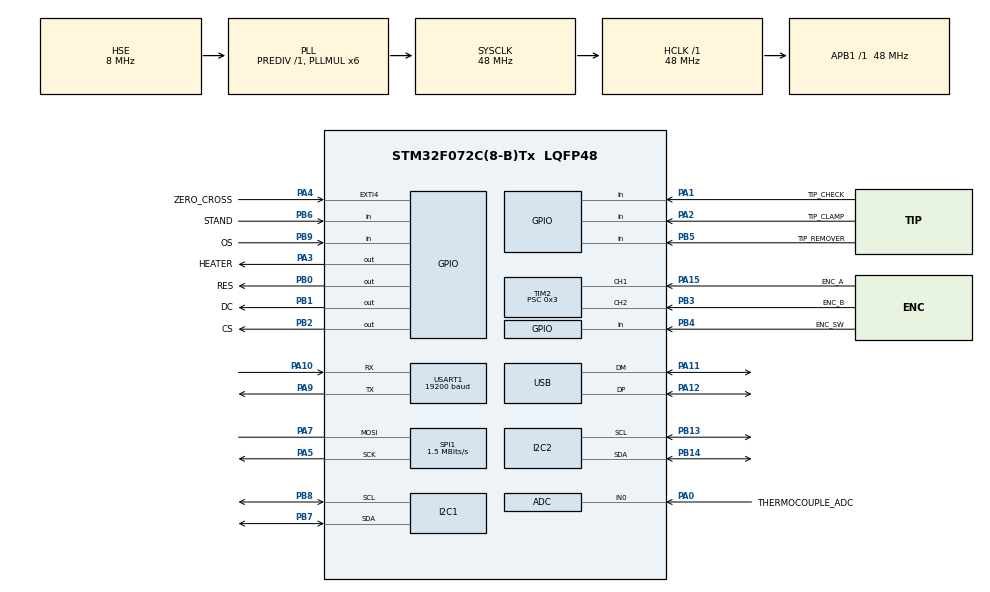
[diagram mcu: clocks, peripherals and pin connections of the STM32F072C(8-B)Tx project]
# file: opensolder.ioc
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ADC.ContinuousConvMode=ENABLE
ADC.SamplingTime=ADC_SAMPLETIME_239CYCLES_5
Dma.ADC.0.Direction=DMA_PERIPH_TO_MEMORY
Dma.ADC.0.Instance=DMA1_Channel1
Dma.ADC.0.MemDataAlignment=DMA_MDATAALIGN_HALFWORD
Dma.ADC.0.MemInc=DMA_MINC_ENABLE
Dma.ADC.0.Mode=DMA_NORMAL
Dma.ADC.0.PeriphDataAlignment=DMA_PDATAALIGN_HALFWORD
Dma.ADC.0.PeriphInc=DMA_PINC_DISABLE
Dma.ADC.0.Priority=DMA_PRIORITY_LOW
Dma.Request0=ADC
I2C2.Timing=0x20303E5D
Mcu.Family=STM32F0
Mcu.Name=STM32F072C(8-B)Tx
Mcu.Package=LQFP48
NVIC.DMA1_Channel1_IRQn=true\:0\:0\:false\:false\:true\:false\:true\:true
NVIC.EXTI4_15_IRQn=true\:0\:0\:false\:false\:true\:true\:true\:true
NVIC.TIM14_IRQn=true\:0\:0\:false\:false\:true\:true\:true\:true
NVIC.TIM6_DAC_IRQn=true\:0\:0\:false\:false\:true\:true\:true\:true
NVIC.TIM7_IRQn=true\:0\:0\:false\:false\:true\:true\:true\:true
NVIC.USB_IRQn=true\:0\:0\:false\:false\:true\:false\:true\:true
PA0.GPIO_Label=THERMOCOUPLE_ADC
PA0.Mode=IN0
PA0.Signal=ADC_IN0
PA1.GPIO_Label=TIP_CHECK
PA1.Signal=GPIO_Input
PA10.Mode=Asynchronous
PA10.Signal=USART1_RX
PA11.Mode=Device
PA11.Signal=USB_DM
PA12.Mode=Device
PA12.Signal=USB_DP
PA13.Mode=Serial_Wire
PA13.Signal=SYS_SWDIO
PA14.Mode=Serial_Wire
PA14.Signal=SYS_SWCLK
PA15.GPIO_Label=ENC_A
PA15.Signal=S_TIM2_CH1_ETR
PA2.GPIO_Label=TIP_CLAMP
PA2.Signal=GPIO_Input
PA3.GPIO_Label=HEATER
PA3.Signal=GPIO_Output
PA4.GPIO_Label=ZERO_CROSS
PA4.GPIO_PuPd=GPIO_PULLUP
PA4.Signal=GPXTI4
PA5.Mode=Simplex_Bidirectional_Master
PA5.Signal=SPI1_SCK
PA7.Mode=Simplex_Bidirectional_Master
PA7.Signal=SPI1_MOSI
PA9.Mode=Asynchronous
PA9.Signal=USART1_TX
PB0.GPIO_Label=RES
PB0.Signal=GPIO_Output
PB1.GPIO_Label=DC
PB1.Signal=GPIO_Output
PB13.Mode=I2C
PB13.Signal=I2C2_SCL
PB14.Mode=I2C
PB14.Signal=I2C2_SDA
PB2.GPIO_Label=CS
PB2.Signal=GPIO_Output
PB3.GPIO_Label=ENC_B
PB3.Signal=S_TIM2_CH2
PB4.GPIO_Label=ENC_SW
PB4.Signal=GPIO_Input
PB5.GPIO_Label=TIP_REMOVER
PB5.GPIO_PuPd=GPIO_NOPULL
PB5.Signal=GPIO_Input
PB6.GPIO_Label=STAND
PB6.GPIO_PuPd=GPIO_NOPULL
PB6.Signal=GPIO_Input
PB7.Mode=I2C
PB7.Signal=I2C1_SDA
PB8.Mode=I2C
PB8.Signal=I2C1_SCL
PB9.GPIO_Label=OS
PB9.GPIO_PuPd=GPIO_PULLUP
PB9.Signal=GPIO_Input
PF0-OSC_IN.Mode=HSE-External-Oscillator
PF0-OSC_IN.Signal=RCC_OSC_IN
PF1-OSC_OUT.Mode=HSE-External-Oscillator
PF1-OSC_OUT.Signal=RCC_OSC_OUT
ProjectManager.HeapSize=0x200
ProjectManager.StackSize=0x400
ProjectManager.TargetToolchain=STM32CubeIDE
RCC.AHBFreq_Value=48000000
RCC.APB1Freq_Value=48000000
RCC.APB1TimFreq_Value=48000000
RCC.HCLKFreq_Value=48000000
RCC.PLLMUL=RCC_PLL_MUL6
RCC.PLLSourceVirtual=RCC_PLLSOURCE_HSE
RCC.SYSCLKFreq_VALUE=48000000
RCC.SYSCLKSource=RCC_SYSCLKSOURCE_PLLCLK
SH.S_TIM2_CH1_ETR.0=TIM2_CH1,Encoder_Interface
SH.S_TIM2_CH2.0=TIM2_CH2,Encoder_Interface
SPI1.BaudRatePrescaler=SPI_BAUDRATEPRESCALER_32
SPI1.CLKPolarity=SPI_POLARITY_HIGH
SPI1.CalculateBaudRate=1.5 MBits/s
SPI1.DataSize=SPI_DATASIZE_8BIT
SPI1.Direction=SPI_DIRECTION_1LINE
SPI1.Mode=SPI_MODE_MASTER
SPI1.VirtualType=VM_MASTER
TIM14.AutoReloadPreload=TIM_AUTORELOAD_PRELOAD_ENABLE
TIM14.Period=1999
TIM14.Prescaler=47
TIM2.EncoderMode=TIM_ENCODERMODE_TI12
TIM2.IC1Filter=5
TIM2.IC1Polarity=TIM_ICPOLARITY_FALLING
TIM2.IC2Filter=5
TIM2.IC2Polarity=TIM_ICPOLARITY_FALLING
TIM2.Period=0xffffffff
TIM2.Prescaler=0x3
TIM6.Period=90
TIM6.Prescaler=47
TIM7.Period=1999
TIM7.Prescaler=47
USART1.BaudRate=19200
USART1.VirtualMode-Asynchronous=VM_ASYNC
USB_DEVICE.CLASS_NAME_FS=CDC
USB_DEVICE.VirtualMode=Cdc
USB_DEVICE.VirtualModeFS=Cdc_FS
VP_TIM14_VS_ClockSourceINT.Mode=Enable_Timer
VP_TIM6_VS_ClockSourceINT.Mode=Enable_Timer
VP_TIM7_VS_ClockSourceINT.Mode=Enable_Timer
VP_USB_DEVICE_VS_USB_DEVICE_CDC_FS.Mode=CDC_FS
board=custom

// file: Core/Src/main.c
/* USER CODE BEGIN Header */
/**
  ******************************************************************************
  * @file           : main.c
  * @brief          : Main program body
  ******************************************************************************
  * @attention
  *
  * <h2><center>&copy; Copyright (c) 2021 STMicroelectronics.
  * All rights reserved.</center></h2>
  *
  * This software component is licensed by ST under BSD 3-Clause license,
  * the "License"; You may not use this file except in compliance with the
  * License. You may obtain a copy of the License at:
  *                        opensource.org/licenses/BSD-3-Clause
  *
  ******************************************************************************
  */
/* USER CODE END Header */
#include "main.h"
#include "usb_device.h"

/* USER CODE BEGIN Includes */
#include "opensolder.h"

/* USER CODE END Includes */

ADC_HandleTypeDef hadc;
DMA_HandleTypeDef hdma_adc;

I2C_HandleTypeDef hi2c1;
I2C_HandleTypeDef hi2c2;

SPI_HandleTypeDef hspi1;

TIM_HandleTypeDef htim2;
TIM_HandleTypeDef htim6;
TIM_HandleTypeDef htim7;
TIM_HandleTypeDef htim14;

UART_HandleTypeDef huart1;

void SystemClock_Config(void);
static void MX_GPIO_Init(void);
static void MX_DMA_Init(void);
static void MX_ADC_Init(void);
static void MX_SPI1_Init(void);
static void MX_TIM2_Init(void);
static void MX_TIM6_Init(void);
static void MX_TIM7_Init(void);
static void MX_I2C1_Init(void);
static void MX_I2C2_Init(void);
static void MX_USART1_UART_Init(void);
static void MX_TIM14_Init(void);

int main(void)
{

  /* MCU Configuration--------------------------------------------------------*/

  /* Reset of all peripherals, Initializes the Flash interface and the Systick. */
  HAL_Init();

  /* Configure the system clock */
  SystemClock_Config();

  /* Initialize all configured peripherals */
  MX_GPIO_Init();
  MX_DMA_Init();
  MX_ADC_Init();
  MX_SPI1_Init();
  MX_TIM2_Init();
  MX_TIM6_Init();
  MX_TIM7_Init();
  MX_I2C1_Init();
  MX_I2C2_Init();
  MX_USART1_UART_Init();
  MX_USB_DEVICE_Init();
  MX_TIM14_Init();
  /* USER CODE BEGIN 2 */

  opensolder_init();

  /* USER CODE END 2 */

  /* Infinite loop */
  /* USER CODE BEGIN WHILE */
  while (1)
  {

	opensolder_main();

    /* USER CODE END WHILE */

  }
}

void SystemClock_Config(void)
{
  RCC_OscInitTypeDef RCC_OscInitStruct = {0};
  RCC_ClkInitTypeDef RCC_ClkInitStruct = {0};
  RCC_PeriphCLKInitTypeDef PeriphClkInit = {0};

  /** Initializes the RCC Oscillators according to the specified parameters
  * in the RCC_OscInitTypeDef structure.
  */
  RCC_OscInitStruct.OscillatorType = RCC_OSCILLATORTYPE_HSI|RCC_OSCILLATORTYPE_HSI14
                              |RCC_OSCILLATORTYPE_HSI48|RCC_OSCILLATORTYPE_HSE;
  RCC_OscInitStruct.HSEState = RCC_HSE_ON;
  RCC_OscInitStruct.HSIState = RCC_HSI_ON;
  RCC_OscInitStruct.HSI48State = RCC_HSI48_ON;
  RCC_OscInitStruct.HSI14State = RCC_HSI14_ON;
  RCC_OscInitStruct.HSICalibrationValue = RCC_HSICALIBRATION_DEFAULT;
  RCC_OscInitStruct.HSI14CalibrationValue = 16;
  RCC_OscInitStruct.PLL.PLLState = RCC_PLL_ON;
  RCC_OscInitStruct.PLL.PLLSource = RCC_PLLSOURCE_HSE;
  RCC_OscInitStruct.PLL.PLLMUL = RCC_PLL_MUL6;
  RCC_OscInitStruct.PLL.PREDIV = RCC_PREDIV_DIV1;
  if (HAL_RCC_OscConfig(&RCC_OscInitStruct) != HAL_OK)
  {
    Error_Handler();
  }

  /** Initializes the CPU, AHB and APB buses clocks
  */
  RCC_ClkInitStruct.ClockType = RCC_CLOCKTYPE_HCLK|RCC_CLOCKTYPE_SYSCLK
                              |RCC_CLOCKTYPE_PCLK1;
  RCC_ClkInitStruct.SYSCLKSource = RCC_SYSCLKSOURCE_PLLCLK;
  RCC_ClkInitStruct.AHBCLKDivider = RCC_SYSCLK_DIV1;
  RCC_ClkInitStruct.APB1CLKDivider = RCC_HCLK_DIV1;

  if (HAL_RCC_ClockConfig(&RCC_ClkInitStruct, FLASH_LATENCY_1) != HAL_OK)
  {
    Error_Handler();
  }
  PeriphClkInit.PeriphClockSelection = RCC_PERIPHCLK_USB|RCC_PERIPHCLK_USART1
                              |RCC_PERIPHCLK_I2C1;
  PeriphClkInit.Usart1ClockSelection = RCC_USART1CLKSOURCE_PCLK1;
  PeriphClkInit.I2c1ClockSelection = RCC_I2C1CLKSOURCE_HSI;
  PeriphClkInit.UsbClockSelection = RCC_USBCLKSOURCE_HSI48;

  if (HAL_RCCEx_PeriphCLKConfig(&PeriphClkInit) != HAL_OK)
  {
    Error_Handler();
  }
}

static void MX_ADC_Init(void)
{

  ADC_ChannelConfTypeDef sConfig = {0};

  /** Configure the global features of the ADC (Clock, Resolution, Data Alignment and number of conversion)
  */
  hadc.Instance = ADC1;
  hadc.Init.ClockPrescaler = ADC_CLOCK_ASYNC_DIV1;
  hadc.Init.Resolution = ADC_RESOLUTION_12B;
  hadc.Init.DataAlign = ADC_DATAALIGN_RIGHT;
  hadc.Init.ScanConvMode = ADC_SCAN_DIRECTION_FORWARD;
  hadc.Init.EOCSelection = ADC_EOC_SINGLE_CONV;
  hadc.Init.LowPowerAutoWait = DISABLE;
  hadc.Init.LowPowerAutoPowerOff = DISABLE;
  hadc.Init.ContinuousConvMode = ENABLE;
  hadc.Init.DiscontinuousConvMode = DISABLE;
  hadc.Init.ExternalTrigConv = ADC_SOFTWARE_START;
  hadc.Init.ExternalTrigConvEdge = ADC_EXTERNALTRIGCONVEDGE_NONE;
  hadc.Init.DMAContinuousRequests = DISABLE;
  hadc.Init.Overrun = ADC_OVR_DATA_PRESERVED;
  if (HAL_ADC_Init(&hadc) != HAL_OK)
  {
    Error_Handler();
  }

  /** Configure for the selected ADC regular channel to be converted.
  */
  sConfig.Channel = ADC_CHANNEL_0;
  sConfig.Rank = ADC_RANK_CHANNEL_NUMBER;
  sConfig.SamplingTime = ADC_SAMPLETIME_239CYCLES_5;
  if (HAL_ADC_ConfigChannel(&hadc, &sConfig) != HAL_OK)
  {
    Error_Handler();
  }

}

static void MX_I2C1_Init(void)
{

  hi2c1.Instance = I2C1;
  hi2c1.Init.Timing = 0x2000090E;
  hi2c1.Init.OwnAddress1 = 0;
  hi2c1.Init.AddressingMode = I2C_ADDRESSINGMODE_7BIT;
  hi2c1.Init.DualAddressMode = I2C_DUALADDRESS_DISABLE;
  hi2c1.Init.OwnAddress2 = 0;
  hi2c1.Init.OwnAddress2Masks = I2C_OA2_NOMASK;
  hi2c1.Init.GeneralCallMode = I2C_GENERALCALL_DISABLE;
  hi2c1.Init.NoStretchMode = I2C_NOSTRETCH_DISABLE;
  if (HAL_I2C_Init(&hi2c1) != HAL_OK)
  {
    Error_Handler();
  }

  /** Configure Analogue filter
  */
  if (HAL_I2CEx_ConfigAnalogFilter(&hi2c1, I2C_ANALOGFILTER_ENABLE) != HAL_OK)
  {
    Error_Handler();
  }

  /** Configure Digital filter
  */
  if (HAL_I2CEx_ConfigDigitalFilter(&hi2c1, 0) != HAL_OK)
  {
    Error_Handler();
  }

}

static void MX_I2C2_Init(void)
{

  hi2c2.Instance = I2C2;
  hi2c2.Init.Timing = 0x20303E5D;
  hi2c2.Init.OwnAddress1 = 0;
  hi2c2.Init.AddressingMode = I2C_ADDRESSINGMODE_7BIT;
  hi2c2.Init.DualAddressMode = I2C_DUALADDRESS_DISABLE;
  hi2c2.Init.OwnAddress2 = 0;
  hi2c2.Init.OwnAddress2Masks = I2C_OA2_NOMASK;
  hi2c2.Init.GeneralCallMode = I2C_GENERALCALL_DISABLE;
  hi2c2.Init.NoStretchMode = I2C_NOSTRETCH_DISABLE;
  if (HAL_I2C_Init(&hi2c2) != HAL_OK)
  {
    Error_Handler();
  }

  /** Configure Analogue filter
  */
  if (HAL_I2CEx_ConfigAnalogFilter(&hi2c2, I2C_ANALOGFILTER_ENABLE) != HAL_OK)
  {
    Error_Handler();
  }

  /** Configure Digital filter
  */
  if (HAL_I2CEx_ConfigDigitalFilter(&hi2c2, 0) != HAL_OK)
  {
    Error_Handler();
  }

}

static void MX_SPI1_Init(void)
{

  /* SPI1 parameter configuration*/
  hspi1.Instance = SPI1;
  hspi1.Init.Mode = SPI_MODE_MASTER;
  hspi1.Init.Direction = SPI_DIRECTION_1LINE;
  hspi1.Init.DataSize = SPI_DATASIZE_8BIT;
  hspi1.Init.CLKPolarity = SPI_POLARITY_HIGH;
  hspi1.Init.CLKPhase = SPI_PHASE_1EDGE;
  hspi1.Init.NSS = SPI_NSS_SOFT;
  hspi1.Init.BaudRatePrescaler = SPI_BAUDRATEPRESCALER_32;
  hspi1.Init.FirstBit = SPI_FIRSTBIT_MSB;
  hspi1.Init.TIMode = SPI_TIMODE_DISABLE;
  hspi1.Init.CRCCalculation = SPI_CRCCALCULATION_DISABLE;
  hspi1.Init.CRCPolynomial = 7;
  hspi1.Init.CRCLength = SPI_CRC_LENGTH_DATASIZE;
  hspi1.Init.NSSPMode = SPI_NSS_PULSE_ENABLE;
  if (HAL_SPI_Init(&hspi1) != HAL_OK)
  {
    Error_Handler();
  }

}

static void MX_TIM2_Init(void)
{

  TIM_Encoder_InitTypeDef sConfig = {0};
  TIM_MasterConfigTypeDef sMasterConfig = {0};

  htim2.Instance = TIM2;
  htim2.Init.Prescaler = 0x3;
  htim2.Init.CounterMode = TIM_COUNTERMODE_UP;
  htim2.Init.Period = 0xffffffff;
  htim2.Init.ClockDivision = TIM_CLOCKDIVISION_DIV1;
  htim2.Init.AutoReloadPreload = TIM_AUTORELOAD_PRELOAD_DISABLE;
  sConfig.EncoderMode = TIM_ENCODERMODE_TI12;
  sConfig.IC1Polarity = TIM_ICPOLARITY_FALLING;
  sConfig.IC1Selection = TIM_ICSELECTION_DIRECTTI;
  sConfig.IC1Prescaler = TIM_ICPSC_DIV1;
  sConfig.IC1Filter = 5;
  sConfig.IC2Polarity = TIM_ICPOLARITY_FALLING;
  sConfig.IC2Selection = TIM_ICSELECTION_DIRECTTI;
  sConfig.IC2Prescaler = TIM_ICPSC_DIV1;
  sConfig.IC2Filter = 5;
  if (HAL_TIM_Encoder_Init(&htim2, &sConfig) != HAL_OK)
  {
    Error_Handler();
  }
  sMasterConfig.MasterOutputTrigger = TIM_TRGO_RESET;
  sMasterConfig.MasterSlaveMode = TIM_MASTERSLAVEMODE_DISABLE;
  if (HAL_TIMEx_MasterConfigSynchronization(&htim2, &sMasterConfig) != HAL_OK)
  {
    Error_Handler();
  }

}

static void MX_TIM6_Init(void)
{

  TIM_MasterConfigTypeDef sMasterConfig = {0};

  htim6.Instance = TIM6;
  htim6.Init.Prescaler = 47;
  htim6.Init.CounterMode = TIM_COUNTERMODE_UP;
  htim6.Init.Period = 90;
  htim6.Init.AutoReloadPreload = TIM_AUTORELOAD_PRELOAD_DISABLE;
  if (HAL_TIM_Base_Init(&htim6) != HAL_OK)
  {
    Error_Handler();
  }
  sMasterConfig.MasterOutputTrigger = TIM_TRGO_RESET;
  sMasterConfig.MasterSlaveMode = TIM_MASTERSLAVEMODE_DISABLE;
  if (HAL_TIMEx_MasterConfigSynchronization(&htim6, &sMasterConfig) != HAL_OK)
  {
    Error_Handler();
  }

}

static void MX_TIM7_Init(void)
{

  TIM_MasterConfigTypeDef sMasterConfig = {0};

  htim7.Instance = TIM7;
  htim7.Init.Prescaler = 47;
  htim7.Init.CounterMode = TIM_COUNTERMODE_UP;
  htim7.Init.Period = 1999;
  htim7.Init.AutoReloadPreload = TIM_AUTORELOAD_PRELOAD_DISABLE;
  if (HAL_TIM_Base_Init(&htim7) != HAL_OK)
  {
    Error_Handler();
  }
  sMasterConfig.MasterOutputTrigger = TIM_TRGO_RESET;
  sMasterConfig.MasterSlaveMode = TIM_MASTERSLAVEMODE_DISABLE;
  if (HAL_TIMEx_MasterConfigSynchronization(&htim7, &sMasterConfig) != HAL_OK)
  {
    Error_Handler();
  }

}

static void MX_TIM14_Init(void)
{

  htim14.Instance = TIM14;
  htim14.Init.Prescaler = 47;
  htim14.Init.CounterMode = TIM_COUNTERMODE_UP;
  htim14.Init.Period = 1999;
  htim14.Init.ClockDivision = TIM_CLOCKDIVISION_DIV1;
  htim14.Init.AutoReloadPreload = TIM_AUTORELOAD_PRELOAD_ENABLE;
  if (HAL_TIM_Base_Init(&htim14) != HAL_OK)
  {
    Error_Handler();
  }

}

static void MX_USART1_UART_Init(void)
{

  huart1.Instance = USART1;
  huart1.Init.BaudRate = 19200;
  huart1.Init.WordLength = UART_WORDLENGTH_8B;
  huart1.Init.StopBits = UART_STOPBITS_1;
  huart1.Init.Parity = UART_PARITY_NONE;
  huart1.Init.Mode = UART_MODE_TX_RX;
  huart1.Init.HwFlowCtl = UART_HWCONTROL_NONE;
  huart1.Init.OverSampling = UART_OVERSAMPLING_16;
  huart1.Init.OneBitSampling = UART_ONE_BIT_SAMPLE_DISABLE;
  huart1.AdvancedInit.AdvFeatureInit = UART_ADVFEATURE_NO_INIT;
  if (HAL_UART_Init(&huart1) != HAL_OK)
  {
    Error_Handler();
  }

}

static void MX_DMA_Init(void)
{

  /* DMA controller clock enable */
  __HAL_RCC_DMA1_CLK_ENABLE();

  /* DMA interrupt init */
  /* DMA1_Channel1_IRQn interrupt configuration */
  HAL_NVIC_SetPriority(DMA1_Channel1_IRQn, 0, 0);
  HAL_NVIC_EnableIRQ(DMA1_Channel1_IRQn);

}

static void MX_GPIO_Init(void)
{
  GPIO_InitTypeDef GPIO_InitStruct = {0};

  /* GPIO Ports Clock Enable */
  __HAL_RCC_GPIOF_CLK_ENABLE();
  __HAL_RCC_GPIOA_CLK_ENABLE();
  __HAL_RCC_GPIOB_CLK_ENABLE();

  /*Configure GPIO pin Output Level */
  HAL_GPIO_WritePin(HEATER_GPIO_Port, HEATER_Pin, GPIO_PIN_RESET);

  /*Configure GPIO pin Output Level */
  HAL_GPIO_WritePin(GPIOB, RES_Pin|DC_Pin|CS_Pin, GPIO_PIN_RESET);

  /*Configure GPIO pins : TIP_CHECK_Pin TIP_CLAMP_Pin */
  GPIO_InitStruct.Pin = TIP_CHECK_Pin|TIP_CLAMP_Pin;
  GPIO_InitStruct.Mode = GPIO_MODE_INPUT;
  GPIO_InitStruct.Pull = GPIO_NOPULL;
  HAL_GPIO_Init(GPIOA, &GPIO_InitStruct);

  /*Configure GPIO pin : HEATER_Pin */
  GPIO_InitStruct.Pin = HEATER_Pin;
  GPIO_InitStruct.Mode = GPIO_MODE_OUTPUT_PP;
  GPIO_InitStruct.Pull = GPIO_NOPULL;
  GPIO_InitStruct.Speed = GPIO_SPEED_FREQ_LOW;
  HAL_GPIO_Init(HEATER_GPIO_Port, &GPIO_InitStruct);

  /*Configure GPIO pin : ZERO_CROSS_Pin */
  GPIO_InitStruct.Pin = ZERO_CROSS_Pin;
  GPIO_InitStruct.Mode = GPIO_MODE_IT_RISING;
  GPIO_InitStruct.Pull = GPIO_PULLUP;
  HAL_GPIO_Init(ZERO_CROSS_GPIO_Port, &GPIO_InitStruct);

  /*Configure GPIO pins : RES_Pin DC_Pin CS_Pin */
  GPIO_InitStruct.Pin = RES_Pin|DC_Pin|CS_Pin;
  GPIO_InitStruct.Mode = GPIO_MODE_OUTPUT_PP;
  GPIO_InitStruct.Pull = GPIO_NOPULL;
  GPIO_InitStruct.Speed = GPIO_SPEED_FREQ_LOW;
  HAL_GPIO_Init(GPIOB, &GPIO_InitStruct);

  /*Configure GPIO pins : ENC_SW_Pin TIP_REMOVER_Pin STAND_Pin */
  GPIO_InitStruct.Pin = ENC_SW_Pin|TIP_REMOVER_Pin|STAND_Pin;
  GPIO_InitStruct.Mode = GPIO_MODE_INPUT;
  GPIO_InitStruct.Pull = GPIO_NOPULL;
  HAL_GPIO_Init(GPIOB, &GPIO_InitStruct);

  /*Configure GPIO pin : OS_Pin */
  GPIO_InitStruct.Pin = OS_Pin;
  GPIO_InitStruct.Mode = GPIO_MODE_INPUT;
  GPIO_InitStruct.Pull = GPIO_PULLUP;
  HAL_GPIO_Init(OS_GPIO_Port, &GPIO_InitStruct);

  /* EXTI interrupt init*/
  HAL_NVIC_SetPriority(EXTI4_15_IRQn, 0, 0);
  HAL_NVIC_EnableIRQ(EXTI4_15_IRQn);

}

void Error_Handler(void)
{
  __disable_irq();
  while (1)
  {
  }
}
